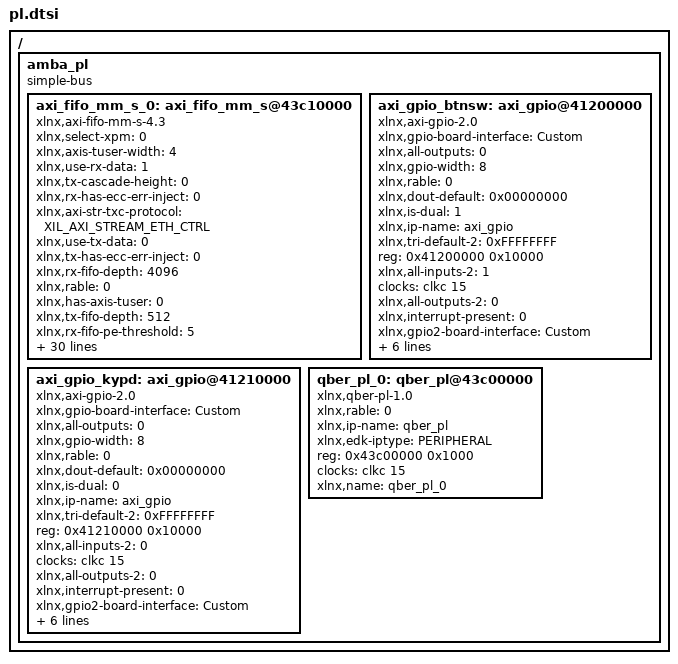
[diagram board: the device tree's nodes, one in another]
/ {
	amba_pl: amba_pl {
		ranges;
		compatible = "simple-bus";
		#address-cells = <1>;
		#size-cells = <1>;
		axi_fifo_mm_s_0: axi_fifo_mm_s@43c10000 {
			xlnx,select-xpm = <0>;
			xlnx,axis-tuser-width = <4>;
			compatible = "xlnx,axi-fifo-mm-s-4.3";
			xlnx,use-rx-data = <1>;
			xlnx,tx-cascade-height = <0>;
			xlnx,rx-has-ecc-err-inject = <0>;
			xlnx,axi-str-txc-protocol = "XIL_AXI_STREAM_ETH_CTRL";
			xlnx,use-tx-data = <0>;
			xlnx,tx-has-ecc-err-inject = <0>;
			xlnx,rx-fifo-depth = <4096>;
			xlnx,rable = <0>;
			xlnx,has-axis-tuser = <0>;
			xlnx,tx-fifo-depth = <512>;
			xlnx,rx-fifo-pe-threshold = <5>;
			xlnx,data-interface-type = <0>;
			xlnx,ip-name = "axi_fifo_mm_s";
			xlnx,use-tx-ctrl = <0>;
			xlnx,rx-fifo-pf-threshold = <4091>;
			xlnx,axis-tid-width = <4>;
			reg = <0x43c10000 0x10000>;
			clocks = <&clkc 15>;
			xlnx,tx-fifo-pe-threshold = <5>;
			xlnx,tx-fifo-pf-threshold = <507>;
			xlnx,s-axi4-data-width = <32>;
			xlnx,has-axis-tstrb = <0>;
			xlnx,axi-str-rxd-protocol = "XIL_AXI_STREAM_ETH_DATA";
			xlnx,use-rx-cut-through = <0>;
			xlnx,axi-str-rxd-tdata-width = <32>;
			xlnx,axis-tdest-width = <4>;
			xlnx,has-axis-tkeep = <0>;
			xlnx,has-axis-tid = <0>;
			xlnx,edk-iptype = "PERIPHERAL";
			xlnx,axi-str-txc-tdata-width = <32>;
			xlnx,axi-str-txd-protocol = "XIL_AXI_STREAM_ETH_DATA";
			xlnx,use-tx-cut-through = <0>;
			xlnx,axi-str-txd-tdata-width = <32>;
			xlnx,rx-enable-ecc = <0>;
			status = "okay";
			clock-names = "s_axi_aclk";
			xlnx,has-axis-tdest = <0>;
			xlnx,tx-enable-ecc = <0>;
			xlnx,s-axi-id-width = <4>;
			xlnx,rx-cascade-height = <0>;
			xlnx,name = "axi_fifo_mm_s_0";
		};
		axi_gpio_btnsw: axi_gpio@41200000 {
			xlnx,gpio-board-interface = "Custom";
			compatible = "xlnx,axi-gpio-2.0" , "xlnx,xps-gpio-1.00.a";
			xlnx,all-outputs = <0>;
			xlnx,gpio-width = <8>;
			xlnx,rable = <0>;
			xlnx,dout-default = <0x00000000>;
			xlnx,is-dual = <1>;
			xlnx,ip-name = "axi_gpio";
			xlnx,tri-default-2 = <0xFFFFFFFF>;
			reg = <0x41200000 0x10000>;
			xlnx,all-inputs-2 = <1>;
			clocks = <&clkc 15>;
			xlnx,all-outputs-2 = <0>;
			xlnx,interrupt-present = <0>;
			xlnx,gpio2-board-interface = "Custom";
			xlnx,edk-iptype = "PERIPHERAL";
			xlnx,dout-default-2 = <0x00000000>;
			xlnx,gpio2-width = <5>;
			status = "okay";
			clock-names = "s_axi_aclk";
			xlnx,tri-default = <0xFFFFFFFF>;
			xlnx,name = "axi_gpio_btnsw";
			xlnx,all-inputs = <1>;
		};
		axi_gpio_kypd: axi_gpio@41210000 {
			xlnx,gpio-board-interface = "Custom";
			compatible = "xlnx,axi-gpio-2.0" , "xlnx,xps-gpio-1.00.a";
			xlnx,all-outputs = <0>;
			xlnx,gpio-width = <8>;
			xlnx,rable = <0>;
			xlnx,dout-default = <0x00000000>;
			xlnx,is-dual = <0>;
			xlnx,ip-name = "axi_gpio";
			xlnx,tri-default-2 = <0xFFFFFFFF>;
			reg = <0x41210000 0x10000>;
			xlnx,all-inputs-2 = <0>;
			clocks = <&clkc 15>;
			xlnx,all-outputs-2 = <0>;
			xlnx,interrupt-present = <0>;
			xlnx,gpio2-board-interface = "Custom";
			xlnx,edk-iptype = "PERIPHERAL";
			xlnx,dout-default-2 = <0x00000000>;
			xlnx,gpio2-width = <32>;
			status = "okay";
			clock-names = "s_axi_aclk";
			xlnx,tri-default = <0xFFFFFFFF>;
			xlnx,name = "axi_gpio_kypd";
			xlnx,all-inputs = <0>;
		};
		qber_pl_0: qber_pl@43c00000 {
			xlnx,rable = <0>;
			compatible = "xlnx,qber-pl-1.0";
			status = "okay";
			clock-names = "aclk";
			xlnx,ip-name = "qber_pl";
			xlnx,edk-iptype = "PERIPHERAL";
			reg = <0x43c00000 0x1000>;
			clocks = <&clkc 15>;
			xlnx,name = "qber_pl_0";
		};
	};
};
